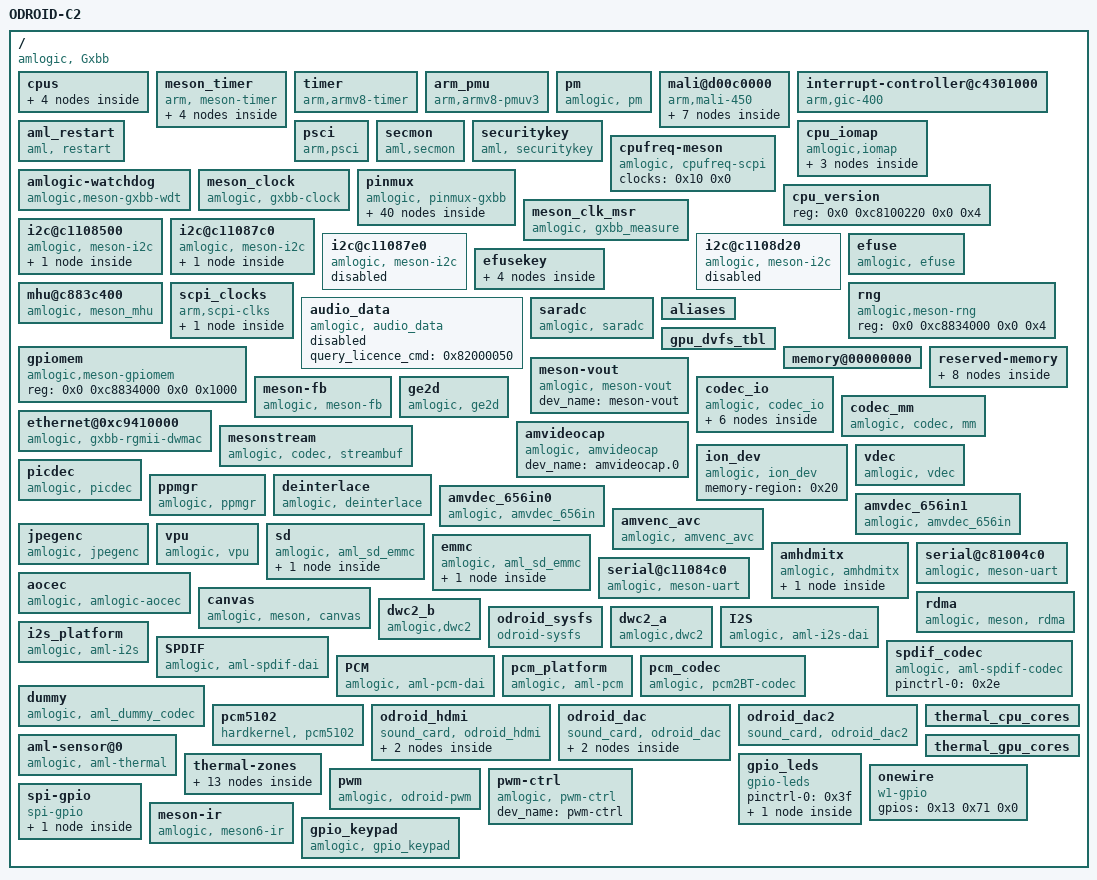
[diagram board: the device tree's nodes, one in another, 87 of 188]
/dts-v1/;

/ {
	compatible = "amlogic, Gxbb";
	model = "ODROID-C2";
	interrupt-parent = <0x1>;
	#address-cells = <0x2>;
	#size-cells = <0x2>;

	cpus {
		#address-cells = <0x2>;
		#size-cells = <0x0>;
		#cooling-cells = <0x2>;
		linux,phandle = <0x3a>;
		phandle = <0x3a>;

		cpu@0 {
			device_type = "cpu";
			compatible = "arm,cortex-a53", "arm,armv8";
			reg = <0x0 0x0>;
			enable-method = "psci";
			timer = <0x2>;
		};

		cpu@1 {
			device_type = "cpu";
			compatible = "arm,cortex-a53", "arm,armv8";
			reg = <0x0 0x1>;
			enable-method = "psci";
			timer = <0x4>;
		};

		cpu@2 {
			device_type = "cpu";
			compatible = "arm,cortex-a53", "arm,armv8";
			reg = <0x0 0x2>;
			enable-method = "psci";
			timer = <0x5>;
		};

		cpu@3 {
			device_type = "cpu";
			compatible = "arm,cortex-a53", "arm,armv8";
			reg = <0x0 0x3>;
			enable-method = "psci";
			timer = <0x6>;
		};
	};

	meson_timer {
		compatible = "arm, meson-timer";
		#address-cells = <0x2>;
		#size-cells = <0x2>;
		ranges;
		reg = <0x0 0xc1109990 0x0 0x4 0x0 0xc1109988 0x0 0x4>;

		timer-f {
			timer_name = "MESON TIMER-F";
			clockevent-rating = <0x12c>;
			clockevent-shift = <0x14>;
			clockevent-features = <0x3>;
			interrupts = <0x0 0x3c 0x1>;
			bit_enable = <0x10>;
			bit_mode = <0xc>;
			bit_resolution = <0x0>;
			reg = <0x0 0xc1109994 0x0 0x4>;
			linux,phandle = <0x2>;
			phandle = <0x2>;
		};

		timer-g {
			timer_name = "MESON TIMER-G";
			clockevent-rating = <0x12c>;
			clockevent-shift = <0x14>;
			clockevent-features = <0x3>;
			interrupts = <0x0 0x3d 0x1>;
			bit_enable = <0x11>;
			bit_mode = <0xd>;
			bit_resolution = <0x2>;
			reg = <0x0 0xc1109998 0x0 0x4>;
			linux,phandle = <0x4>;
			phandle = <0x4>;
		};

		timer-h {
			timer_name = "MESON TIMER-H";
			clockevent-rating = <0x12c>;
			clockevent-shift = <0x14>;
			clockevent-features = <0x3>;
			interrupts = <0x0 0x3e 0x1>;
			bit_enable = <0x12>;
			bit_mode = <0xe>;
			bit_resolution = <0x4>;
			reg = <0x0 0xc110999c 0x0 0x4>;
			linux,phandle = <0x5>;
			phandle = <0x5>;
		};

		timer-i {
			timer_name = "MESON TIMER-I";
			clockevent-rating = <0x12c>;
			clockevent-shift = <0x14>;
			clockevent-features = <0x3>;
			interrupts = <0x0 0x3f 0x1>;
			bit_enable = <0x13>;
			bit_mode = <0xf>;
			bit_resolution = <0x6>;
			reg = <0x0 0xc11099a0 0x0 0x4>;
			linux,phandle = <0x6>;
			phandle = <0x6>;
		};
	};

	timer {
		compatible = "arm,armv8-timer";
		interrupts = <0x1 0xd 0xff01 0x1 0xe 0xff01 0x1 0xb 0xff01 0x1 0xa 0xff01>;
	};

	arm_pmu {
		compatible = "arm,armv8-pmuv3";
		interrupts = <0x0 0x89 0x4 0x0 0x8a 0x4 0x0 0x99 0x4 0x0 0x9a 0x4>;
	};

	pm {
		compatible = "amlogic, pm";
		gxbaby-suspend;
		reg = <0x0 0xc81000a8 0x0 0x4 0x0 0xc810023c 0x0 0x4>;
	};

	mali@d00c0000 {
		#cooling-cells = <0x2>;
		compatible = "arm,mali-450";
		interrupt-parent = <0x1>;
		reg = <0x0 0xd00c0000 0x0 0x40000 0x0 0xc883c000 0x0 0x4 0x0 0xc8100000 0x0 0x4>;
		interrupts = <0x0 0xa0 0x4 0x0 0xa1 0x4 0x0 0xa2 0x4 0x0 0xa3 0x4 0x0 0xa4 0x4 0x0 0xa5 0x4 0x0 0xa6 0x4 0x0 0xa7 0x4 0x0 0xa8 0x4 0x0 0xa9 0x4>;
		interrupt-names = "IRQGP", "IRQGPMMU", "IRQPP", "IRQPMU", "IRQPP0", "IRQPPMMU0", "IRQPP1", "IRQPPMMU1", "IRQPP2", "IRQPPMMU2";
		pmu_domain_config = <0x1 0x2 0x4 0x4 0x0 0x0 0x0 0x0 0x0 0x1 0x2 0x0>;
		pmu_switch_delay = <0xffff>;
		num_of_pp = <0x3>;
		def_clk = <0x4>;
		sc_mpp = <0x3>;
		min_pp = <0x3>;
		min_clk = <0x4>;
		tbl = <0x7 0x8 0x9 0xa 0xb 0xc>;
		clocks = <0xd 0x8 0xd 0x9 0xd 0x11 0xd 0x12 0xd 0x1e 0xd 0x15 0xd 0x13 0xd 0x14>;
		clock-names = "fclk_div3", "fclk_div4", "fclk_div5", "fclk_div7", "gp0_pll", "clk_mali", "clk_mali_0", "clk_mali_1";
		control_interval = <0xc8>;
		dvfs_tbl = <0xe>;
		linux,phandle = <0x3d>;
		phandle = <0x3d>;

		clk125_cfg {
			clk_freq = <0x7735940>;
			clk_parent = "fclk_div4";
			clkp_freq = <0x1dcd6500>;
			voltage = <0x47e>;
			keep_count = <0x5>;
			threshold = <0x1e 0x78>;
			linux,phandle = <0x7>;
			phandle = <0x7>;
		};

		clk250_cfg {
			clk_freq = <0xee6b280>;
			clk_parent = "fclk_div4";
			clkp_freq = <0x1dcd6500>;
			voltage = <0x47e>;
			keep_count = <0x5>;
			threshold = <0x50 0xaa>;
		};

		clk285_cfg {
			clk_freq = <0x10fcc140>;
			clk_parent = "fclk_div7";
			clkp_freq = <0x10fcc140>;
			voltage = <0x47e>;
			keep_count = <0x5>;
			threshold = <0x64 0xbe>;
			linux,phandle = <0x8>;
			phandle = <0x8>;
		};

		clk400_cfg {
			clk_freq = <0x17d78400>;
			clk_parent = "fclk_div5";
			clkp_freq = <0x17d78400>;
			voltage = <0x47e>;
			keep_count = <0x5>;
			threshold = <0x98 0xcf>;
			linux,phandle = <0x9>;
			phandle = <0x9>;
		};

		clk500_cfg {
			clk_freq = <0x1dcd6500>;
			clk_parent = "fclk_div4";
			clkp_freq = <0x1dcd6500>;
			voltage = <0x47e>;
			keep_count = <0x5>;
			threshold = <0xb4 0xdc>;
			linux,phandle = <0xa>;
			phandle = <0xa>;
		};

		clk666_cfg {
			clk_freq = <0x27b25a80>;
			clk_parent = "fclk_div3";
			clkp_freq = <0x27b25a80>;
			voltage = <0x47e>;
			keep_count = <0x5>;
			threshold = <0xd2 0xec>;
			linux,phandle = <0xb>;
			phandle = <0xb>;
		};

		clk800_cfg {
			clk_freq = <0x2f34f600>;
			clk_parent = "gp0_pll";
			clkp_freq = <0x2f34f600>;
			voltage = <0x47e>;
			keep_count = <0x5>;
			threshold = <0xe6 0xff>;
			linux,phandle = <0xc>;
			phandle = <0xc>;
		};
	};

	interrupt-controller@c4301000 {
		compatible = "arm,gic-400", "arm,cortex-a15-gic", "arm,cortex-a9-gic";
		#interrupt-cells = <0x3>;
		#address-cells = <0x0>;
		interrupt-controller;
		reg = <0x0 0xc4301000 0x0 0x1000 0x0 0xc4302000 0x0 0x2000 0x0 0xc4304000 0x0 0x2000 0x0 0xc4306000 0x0 0x2000>;
		interrupts = <0x1 0x9 0xf04>;
		linux,phandle = <0x1>;
		phandle = <0x1>;
	};

	aml_restart {
		compatible = "aml, restart";
		sys_reset = <0x84000009>;
		sys_poweroff = <0x84000008>;
	};

	psci {
		compatible = "arm,psci";
		method = "smc";
		cpu_suspend = <0xc4000001>;
		cpu_off = <0x84000002>;
		cpu_on = <0xc4000003>;
		migrate = <0xc4000005>;
	};

	secmon {
		compatible = "aml,secmon";
		memory-region = <0xf>;
		in_base_func = <0x82000020>;
		out_base_func = <0x82000021>;
	};

	securitykey {
		compatible = "aml, securitykey";
		storage_query = <0x82000060>;
		storage_read = <0x82000061>;
		storage_write = <0x82000062>;
		storage_tell = <0x82000063>;
		storage_verify = <0x82000064>;
		storage_status = <0x82000065>;
		storage_list = <0x82000067>;
		storage_remove = <0x82000068>;
		storage_in_func = <0x82000023>;
		storage_out_func = <0x82000024>;
		storage_block_func = <0x82000025>;
		storage_size_func = <0x82000027>;
	};

	cpu_iomap {
		compatible = "amlogic,iomap";
		#address-cells = <0x2>;
		#size-cells = <0x2>;
		ranges;

		io_cbus_base {
			reg = <0x0 0xc1100000 0x0 0x100000>;
		};

		io_apb_base {
			reg = <0x0 0xd0000000 0x0 0x200000>;
		};

		io_aobus_base {
			reg = <0x0 0xc8100000 0x0 0x100000>;
		};
	};

	cpufreq-meson {
		compatible = "amlogic, cpufreq-scpi";
		status = "okay";
		clocks = <0x10 0x0>;
		clock-names = "cpu_clk";
	};

	amlogic-watchdog {
		compatible = "amlogic,meson-gxbb-wdt";
		status = "okay";
		reg = <0x0 0xc11098d0 0x0 0x10>;
		clocks = <0xd 0x2>;
	};

	meson_clock {
		compatible = "amlogic, gxbb-clock";
		reg = <0x0 0xc883c000 0x0 0x1000 0x0 0xc8100000 0x0 0x1000>;
		#clock-cells = <0x1>;
		#reset-cells = <0x1>;
		sys_max = <0x5b8d8000>;
		linux,phandle = <0xd>;
		phandle = <0xd>;
	};

	pinmux {
		compatible = "amlogic, pinmux-gxbb";
		dev_name = "pinmux";
		#pinmux-cells = <0x2>;
		#address-cells = <0x2>;
		#size-cells = <0x2>;
		reg = <0x0 0xc1109880 0x0 0x10>;
		interrupts = <0x0 0x40 0x1 0x0 0x41 0x1 0x0 0x42 0x1 0x0 0x43 0x1 0x0 0x44 0x1 0x0 0x45 0x1 0x0 0x46 0x1 0x0 0x47 0x1>;
		ranges;

		banks@c11080b0 {
			reg = <0x0 0xc88344b0 0x0 0x28 0x0 0xc88344e8 0x0 0x14 0x0 0xc8834120 0x0 0x14 0x0 0xc8834430 0x0 0x40>;
			reg-names = "mux", "pull", "pull-enable", "gpio";
			gpio-controller;
			#gpio-cells = <0x2>;
			linux,phandle = <0x13>;
			phandle = <0x13>;
		};

		ao-bank@c1108030 {
			reg = <0x0 0xc8100014 0x0 0x8 0x0 0xc810002c 0x0 0x4 0x0 0xc8100024 0x0 0x8>;
			reg-names = "mux", "pull", "gpio";
			gpio-controller;
			#gpio-cells = <0x2>;
			linux,phandle = <0x25>;
			phandle = <0x25>;
		};

		eth_pins {
			amlogic,setmask = <0x6 0x3fff>;
			amlogic,clrmask = <0x6 0xc000 0x5 0x3c0000f0 0x4 0x300>;
			amlogic,pins = "GPIOZ_0", "GPIOZ_1", "GPIOZ_2", "GPIOZ_3", "GPIOZ_4", "GPIOZ_5", "GPIOZ_6", "GPIOZ_7", "GPIOZ_8", "GPIOZ_9", "GPIOZ_10", "GPIOZ_11", "GPIOZ_12", "GPIOZ_13", "GPIOZ_15";
			linux,phandle = <0x1f>;
			phandle = <0x1f>;
		};

		remote_pin {
			amlogic,setmask = <0x10 0x1>;
			amlogic,pins = "GPIOAO_7";
			linux,phandle = <0x42>;
			phandle = <0x42>;
		};

		ao_uart {
			amlogic,setmask = <0x10 0x1800>;
			amlogic,pins = "GPIOAO_0", "GPIOAO_1";
			linux,phandle = <0x2c>;
			phandle = <0x2c>;
		};

		ao_b_uart {
			amlogic,setmask = <0x10 0x1800000>;
			amlogic,pins = "GPIOAO_4", "GPIOAO_5";
		};

		a_uart {
			amlogic,setmask = <0x4 0x3c00>;
			amlogic,pins = "GPIOX_12", "GPIOX_13", "GPIOX_14", "GPIOX_15";
			linux,phandle = <0x2d>;
			phandle = <0x2d>;
		};

		b_uart {
			amlogic,setmask = <0x2 0x30000000>;
			amlogic,pins = "GPIODV_24", "GPIODV_25";
		};

		c_uart {
			amlogic,setmask = <0x1 0xc0000>;
			amlogic,pins = "GPIOY_13", "GPIOY_14";
		};

		wifi_32k_pins {
			amlogic,setmask = <0x2 0x40000000>;
			amlogic,clrmask = <0x2 0x400000 0x3 0x8000>;
			amlogic,pins = "GPIOX_19";
		};

		sd_clk_cmd_pins {
			amlogic,setmask = <0x2 0xc00 0x10 0x1800>;
			amlogic,pins = "CARD_2", "CARD_3";
			amlogic,enable-output = <0x1>;
			amlogic,pullup = <0x1>;
			amlogic,pullupen = <0x1>;
			linux,phandle = <0x23>;
			phandle = <0x23>;
		};

		sd_all_pins {
			amlogic,setmask = <0x2 0xfc00 0x10 0x1800>;
			amlogic,pins = "CARD_0", "CARD_1", "CARD_2", "CARD_3", "CARD_4", "CARD_5";
			amlogic,enable-output = <0x1>;
			amlogic,pullup = <0x1>;
			amlogic,pullupen = <0x1>;
			linux,phandle = <0x24>;
			phandle = <0x24>;
		};

		sd_1bit_pins {
			amlogic,setmask = <0x2 0x8c00 0x10 0x1800>;
			amlogic,pins = "CARD_1", "CARD_2", "CARD_3";
			amlogic,enable-output = <0x1>;
			amlogic,pullup = <0x1>;
			amlogic,pullupen = <0x1>;
		};

		sd_clk_cmd_uart_pins {
			amlogic,setmask = <0x2 0xc00 0x8 0x600>;
			amlogic,pins = "CARD_2", "CARD_3";
			amlogic,enable-output = <0x1>;
			amlogic,pullup = <0x1>;
			amlogic,pullupen = <0x1>;
		};

		sd_1bit_uart_pins {
			amlogic,setmask = <0x2 0x8c00 0x8 0x600>;
			amlogic,pins = "CARD_1", "CARD_2", "CARD_3";
			amlogic,enable-output = <0x1>;
			amlogic,pullup = <0x1>;
			amlogic,pullupen = <0x1>;
		};

		sd_to_ao_uart_pins {
			amlogic,setmask = <0x10 0x1800>;
			amlogic,clrmask = <0x8 0x600>;
			amlogic,pins = "GPIOAO_0", "GPIOAO_1";
			amlogic,enable-output = <0x1>;
			amlogic,pullup = <0x1>;
			amlogic,pullupen = <0x1>;
		};

		ao_to_sd_uart_pins {
			amlogic,setmask = <0x8 0x600>;
			amlogic,clrmask = <0x10 0x1800 0x2 0x3000>;
			amlogic,pins = "CARD_4", "CARD_5";
			amlogic,enable-output = <0x1>;
			amlogic,pullup = <0x1>;
			amlogic,pullupen = <0x1>;
		};

		emmc_clk_cmd_pins {
			amlogic,setmask = <0x4 0xc00c0000>;
			amlogic,pins = "BOOT_8", "BOOT_10";
			amlogic,enable-output = <0x1>;
			amlogic,pullup = <0x1>;
			amlogic,pullupen = <0x1>;
			linux,phandle = <0x26>;
			phandle = <0x26>;
		};

		emmc_all_pins {
			amlogic,setmask = <0x4 0xc00c0000>;
			amlogic,pins = "BOOT_0", "BOOT_1", "BOOT_2", "BOOT_3", "BOOT_4", "BOOT_5", "BOOT_6", "BOOT_7", "BOOT_8", "BOOT_10";
			amlogic,enable-output = <0x1>;
			amlogic,pullup = <0x1>;
			amlogic,pullupen = <0x1>;
			linux,phandle = <0x27>;
			phandle = <0x27>;
		};

		sdio_clk_cmd_pins {
			amlogic,setmask = <0x8 0x3>;
			amlogic,pins = "GPIOX_4", "GPIOX_5";
			amlogic,enable-output = <0x1>;
			amlogic,pullup = <0x1>;
			amlogic,pullupen = <0x1>;
		};

		sdio_all_pins {
			amlogic,setmask = <0x8 0x3f>;
			amlogic,pins = "GPIOX_0", "GPIOX_1", "GPIOX_2", "GPIOX_3", "GPIOX_4", "GPIOX_5";
			amlogic,enable-output = <0x1>;
			amlogic,pullup = <0x1>;
			amlogic,pullupen = <0x1>;
		};

		conf_nand_pulldown {
			amlogic,pins = "BOOT_0", "BOOT_1", "BOOT_2", "BOOT_3", "BOOT_4", "BOOT_5", "BOOT_6", "BOOT_7", "BOOT_15";
			amlogic,pullup = <0x0>;
			amlogic,pullupen = <0x1>;
		};

		conf_nand_pullup {
			amlogic,pins = "BOOT_8", "BOOT_10";
			amlogic,pullup = <0x1>;
			amlogic,pullupen = <0x1>;
		};

		all_nand_pins {
			amlogic,setmask = <0x4 0x7ff00000>;
			amlogic,clrmask = <0x0 0x80000 0x4 0x800c0000 0x5 0xf>;
			amlogic,pins = "BOOT_0", "BOOT_1", "BOOT_2", "BOOT_3", "BOOT_4", "BOOT_5", "BOOT_6", "BOOT_7", "BOOT_8", "BOOT_9", "BOOT_10", "BOOT_11", "BOOT_12", "BOOT_13", "BOOT_14", "BOOT_15", "BOOT_16", "BOOT_17";
			amlogic,enable-output = <0x1>;
		};

		nand_cs {
			amlogic,setmask = <0x4 0xc000000>;
			amlogic,clrmask = <0x4 0x40000>;
			amlogic,pins = "BOOT_8", "BOOT_9";
		};

		hdmitx_hpd {
			amlogic,setmask = <0x1 0x4000000>;
			amlogic,pins = "GPIOH_0";
			linux,phandle = <0x28>;
			phandle = <0x28>;
		};

		hdmitx_ddc {
			amlogic,setmask = <0x1 0x3000000>;
			amlogic,pins = "GPIOH_1", "GPIOH_2";
			linux,phandle = <0x29>;
			phandle = <0x29>;
		};

		hdmitx_aocec {
			amlogic,setmask = <0x10 0x8000>;
			amlogic,clrmask = <0x10 0x24000 0x11 0x1>;
			amlogic,pins = "GPIOAO_12";
			linux,phandle = <0x2b>;
			phandle = <0x2b>;
		};

		hdmitx_eecec {
			amlogic,setmask = <0x10 0x4000>;
			amlogic,clrmask = <0x10 0x28000 0x11 0x1>;
			amlogic,pins = "GPIOAO_12";
		};

		a_i2c {
			amlogic,setmask = <0x7 0xc000000>;
			amlogic,clrmask = <0x0 0x18c0 0x2 0x30000000 0x5 0x1800>;
			amlogic,pins = "GPIODV_24", "GPIODV_25";
			linux,phandle = <0x11>;
			phandle = <0x11>;
		};

		b_i2c {
			amlogic,setmask = <0x7 0x3000000>;
			amlogic,clrmask = <0x0 0x600 0x2 0xc000000 0x5 0x700>;
			amlogic,pins = "GPIODV_26", "GPIODV_27";
			linux,phandle = <0x12>;
			phandle = <0x12>;
		};

		c_i2c {
			amlogic,setmask = <0x7 0xc00000>;
			amlogic,clrmask = <0x3 0x700000>;
			amlogic,pins = "GPIODV_28", "GPIODV_29";
			linux,phandle = <0x14>;
			phandle = <0x14>;
		};

		d_i2c {
			amlogic,setmask = <0x4 0xc>;
			amlogic,clrmask = <0x2 0x3000000 0x3 0x1000>;
			amlogic,pins = "GPIOX_16", "GPIOX_17";
			linux,phandle = <0x15>;
			phandle = <0x15>;
		};

		dvb_p_ts0_pins {
			amlogic,setmask = <0x3 0x37>;
			amlogic,clrmask = <0x2 0xf0000 0x1 0x30ff>;
			amlogic,pins = "GPIOY_0", "GPIOY_1", "GPIOY_2", "GPIOY_3", "GPIOY_4", "GPIOY_5", "GPIOY_6", "GPIOY_7", "GPIOY_8", "GPIOY_9", "GPIOY_10";
		};

		dvb_s_ts0_pins {
			amlogic,setmask = <0x3 0x17>;
			amlogic,clrmask = <0x2 0xf0000 0x1 0x7>;
			amlogic,pins = "GPIOY_0", "GPIOY_1", "GPIOY_2", "GPIOY_3";
		};

		audio_pin {
			amlogic,setmask = <0x10 0x78000000>;
			amlogic,clrmask = <0x10 0x40000>;
			amlogic,pins = "GPIOAO_8", "GPIOAO_9", "GPIOAO_10", "GPIOAO_11";
			linux,phandle = <0x34>;
			phandle = <0x34>;
		};

		audio_pin1 {
			amlogic,setmask = <0x10 0x10000>;
			amlogic,clrmask = <0x10 0x40000>;
			amlogic,pins = "GPIOAO_6";
			linux,phandle = <0x2e>;
			phandle = <0x2e>;
		};

		led_pin {
			amlogic,setmask = <0x10 0x0>;
			amlogic,clrmask = <0x10 0x80000018>;
			amlogic,pins = "GPIOAO_13";
			linux,phandle = <0x3f>;
			phandle = <0x3f>;
		};

		odroid_pwm0 {
			amlogic,setmask = <0x3 0x20000>;
			amlogic,clrmask = <0x3 0x200>;
			amlogic,pins = "GPIOX_6";
			linux,phandle = <0x40>;
			phandle = <0x40>;
		};

		odroid_pwm1 {
			amlogic,setmask = <0x3 0x20000 0x3 0x60000>;
			amlogic,clrmask = <0x3 0x300 0x8 0x800>;
			amlogic,pins = "GPIOX_6", "GPIOX_7";
			linux,phandle = <0x41>;
			phandle = <0x41>;
		};
	};

	cpu_version {
		reg = <0x0 0xc8100220 0x0 0x4>;
	};

	meson_clk_msr {
		compatible = "amlogic, gxbb_measure";
		reg = <0x0 0xc110875c 0x0 0x4 0x0 0xc1108764 0x0 0x4>;
	};

	i2c@c1108500 {
		compatible = "amlogic, meson-i2c";
		dev_name = "i2c-A";
		status = "okay";
		reg = <0x0 0xc1108500 0x0 0x20>;
		device_id = <0x1>;
		pinctrl-names = "default";
		pinctrl-0 = <0x11>;
		#address-cells = <0x1>;
		#size-cells = <0x0>;
		use_pio = <0x0>;
		master_i2c_speed = <0x493e0>;
		clocks = <0xd 0xa>;
		clock-names = "clk_i2c";
		resets = <0xd 0x9>;

		pcf8563@51 {
			status = "disabled";
			compatible = "nxp,pcf8563";
			reg = <0x51>;
			#clock-cells = <0x0>;
		};
	};

	i2c@c11087c0 {
		compatible = "amlogic, meson-i2c";
		dev_name = "i2c-B";
		status = "okay";
		reg = <0x0 0xc11087c0 0x0 0x20>;
		device_id = <0x2>;
		pinctrl-names = "default";
		pinctrl-0 = <0x12>;
		#address-cells = <0x1>;
		#size-cells = <0x0>;
		use_pio = <0x0>;
		master_i2c_speed = <0x493e0>;
		clocks = <0xd 0xa>;
		clock-names = "clk_i2c";
		resets = <0xd 0x9>;

		sx865x@49 {
			status = "okay";
			compatible = "semtech,sx8650";
			reg = <0x49>;
			#clock-cells = <0x0>;
			gpio-pendown = <0x13 0x52 0x0>;
			gpio-reset = <0x13 0x58 0x0>;
			invert-x = <0x0>;
			invert-y = <0x1>;
			swap-xy = <0x1>;
		};
	};

	i2c@c11087e0 {
		compatible = "amlogic, meson-i2c";
		dev_name = "i2c-C";
		status = "disabled";
		reg = <0x0 0xc11087e0 0x0 0x20>;
		device_id = <0x3>;
		pinctrl-names = "default";
		pinctrl-0 = <0x14>;
		#address-cells = <0x1>;
		#size-cells = <0x0>;
		use_pio = <0x0>;
		master_i2c_speed = <0x493e0>;
		clocks = <0xd 0xa>;
		clock-names = "clk_i2c";
		resets = <0xd 0x9>;
	};

	i2c@c1108d20 {
		compatible = "amlogic, meson-i2c";
		dev_name = "i2c-D";
		status = "disabled";
		reg = <0x0 0xc1108d20 0x0 0x20>;
		device_id = <0x4>;
		pinctrl-names = "default";
		pinctrl-0 = <0x15>;
		#address-cells = <0x1>;
		#size-cells = <0x0>;
		use_pio = <0x0>;
		master_i2c_speed = <0x493e0>;
		clocks = <0xd 0xa>;
		clock-names = "clk_i2c";
		resets = <0xd 0x9>;
	};

	efuse {
		compatible = "amlogic, efuse";
		read_cmd = <0x82000030>;
		write_cmd = <0x82000031>;
		get_max_cmd = <0x82000033>;
		key = <0x16>;
		resets = <0xd 0x3e>;
		reset-names = "efuse_clk";
		status = "okay";
	};

	efusekey {
		keynum = <0x4>;
		key0 = <0x17>;
		key1 = <0x18>;
		key2 = <0x19>;
		key3 = <0x1a>;
		linux,phandle = <0x16>;
		phandle = <0x16>;

		key0 {
			keyname = "mac";
			offset = <0x0>;
			size = <0x6>;
			linux,phandle = <0x17>;
			phandle = <0x17>;
		};

		key1 {
			keyname = "mac_bt";
			offset = <0x6>;
			size = <0x6>;
			linux,phandle = <0x18>;
			phandle = <0x18>;
		};

		key2 {
			keyname = "mac_wifi";
			offset = <0xc>;
			size = <0x6>;
			linux,phandle = <0x19>;
			phandle = <0x19>;
		};

		key3 {
			keyname = "usid";
			offset = <0x12>;
			size = <0x10>;
			linux,phandle = <0x1a>;
			phandle = <0x1a>;
		};
	};

	mhu@c883c400 {
		compatible = "amlogic, meson_mhu";
		reg = <0x0 0xc883c400 0x0 0x4c 0x0 0xc8013000 0x0 0x800>;
		interrupts = <0x0 0xd1 0x8 0x0 0xd2 0x8>;
		#mbox-cells = <0x1>;
		mbox-names = "cpu_to_scp_low", "cpu_to_scp_high";
		mboxes = <0x1b 0x0 0x1b 0x1>;
		linux,phandle = <0x1b>;
		phandle = <0x1b>;
	};

	scpi_clocks {
		compatible = "arm,scpi-clks";

		scpi_clocks@0 {
			compatible = "arm,scpi-clk-indexed";
			#clock-cells = <0x1>;
			clock-indices = <0x0>;
			clock-output-names = "vcpu";
			linux,phandle = <0x10>;
			phandle = <0x10>;
		};
	};

	rng {
		compatible = "amlogic,meson-rng";
		reg = <0x0 0xc8834000 0x0 0x4>;
	};

	audio_data {
		compatible = "amlogic, audio_data";
		query_licence_cmd = <0x82000050>;
		status = "disabled";
	};

	saradc {
		compatible = "amlogic, saradc";
		status = "okay";
		interrupts = <0x0 0x9 0x1>;
		interrupt-names = "saradc_int";
		clocks = <0xd 0x2>;
		clock-names = "saradc_clk";
		resets = <0xd 0x56>;
		reg = <0x0 0xc1108680 0x0 0x30 0x0 0xc883c3d8 0x0 0x8>;
	};

	aliases {
		serial0 = "/serial@c81004c0";
		serial1 = "/serial@c11084c0";
	};

	gpu_dvfs_tbl {
		sc_mpp = <0x3>;
		tbl = <0x8 0x9 0xa 0xb 0xc>;
		linux,phandle = <0xe>;
		phandle = <0xe>;
	};

	gpiomem {
		compatible = "amlogic,meson-gpiomem";
		reg = <0x0 0xc8834000 0x0 0x1000>;
		status = "okay";
	};

	memory@00000000 {
		device_type = "memory";
		linux,usable-memory = <0x0 0x1000000 0x0 0x7f000000>;
	};

	reserved-memory {
		#address-cells = <0x2>;
		#size-cells = <0x2>;
		ranges;

		linux,secmon {
			compatible = "aml_secmon_memory";
			reg = <0x0 0x10000000 0x0 0x200000>;
			no-map;
			linux,phandle = <0xf>;
			phandle = <0xf>;
		};

		linux,meson-fb {
			compatible = "amlogic, fb-memory";
			size = <0x0 0x8000000>;
			no-map;
			linux,phandle = <0x1c>;
			phandle = <0x1c>;
		};

		linux,di {
			compatible = "amlogic, di-mem";
			size = <0x0 0x1e00000>;
			multi-use;
			linux,phandle = <0x22>;
			phandle = <0x22>;
		};

		linux,ion-dev {
			compatible = "amlogic, idev-mem";
			size = <0x0 0x2000000>;
			multi-use;
			linux,phandle = <0x20>;
			phandle = <0x20>;
		};

		linux,codec_mm_cma {
			compatible = "shared-dma-pool";
			reusable;
			size = <0x0 0xbc00000>;
			alignment = <0x0 0x400000>;
			linux,contiguous-region;
			linux,phandle = <0x1d>;
			phandle = <0x1d>;
		};

		linux,picdec {
			compatible = "shared-dma-pool";
			reusable;
			size = <0x0 0x3000000>;
			alignment = <0x0 0x400000>;
			linux,contiguous-region;
			linux,phandle = <0x21>;
			phandle = <0x21>;
		};

		linux,codec_mm_reserved {
			compatible = "amlogic, codec-mm-reserved";
			size = <0x0 0x4100000>;
			alignment = <0x0 0x100000>;
			linux,phandle = <0x1e>;
			phandle = <0x1e>;
		};

		linux,jpegenc_cma {
			compatible = "shared-dma-pool";
			linux,phandle = <0x3>;
			reusable;
			size = <0x0 0x2400000>;
			alignment = <0x0 0x400000>;
		};
	};

	meson-vout {
		compatible = "amlogic, meson-vout";
		dev_name = "meson-vout";
		status = "okay";
	};

	meson-fb {
		compatible = "amlogic, meson-fb";
		memory-region = <0x1c>;
		dev_name = "meson-fb";
		status = "okay";
		interrupts = <0x0 0x3 0x1 0x0 0x59 0x1>;
		interrupt-names = "viu-vsync", "rdma";
		mem_size = <0x6000000 0x100000>;
		vmode = <0x3>;
		scale_mode = <0x1>;
		4k2k_fb = <0x1>;
		display_size_default = <0x780 0x438 0x780 0x870 0x20>;
	};

	ge2d {
		compatible = "amlogic, ge2d";
		dev_name = "ge2d";
		status = "okay";
		interrupts = <0x0 0x96 0x1>;
		interrupt-names = "ge2d";
		clocks = <0xd 0x17 0xd 0x19>;
		clock-names = "clk_vapb_0", "clk_ge2d";
		resets = <0xd 0x34>;
		reset-names = "ge2d";
	};

	codec_io {
		compatible = "amlogic, codec_io";
		#address-cells = <0x2>;
		#size-cells = <0x2>;
		ranges;

		io_cbus_base {
			reg = <0x0 0xc1100000 0x0 0x100000>;
		};

		io_dos_base {
			reg = <0x0 0xc8820000 0x0 0x10000>;
		};

		io_hiubus_base {
			reg = <0x0 0xc883c000 0x0 0x2000>;
		};

		io_aobus_base {
			reg = <0x0 0xc8100000 0x0 0x100000>;
		};

		io_vcbus_base {
			reg = <0x0 0xd0100000 0x0 0x40000>;
		};

		io_dmc_base {
			reg = <0x0 0xc8838000 0x0 0x400>;
		};
	};

	codec_mm {
		compatible = "amlogic, codec, mm";
		memory-region = <0x1d 0x1e>;
		dev_name = "codec_mm";
		status = "okay";
	};

	ethernet@0xc9410000 {
		compatible = "amlogic, gxbb-rgmii-dwmac";
		reg = <0x0 0xc9410000 0x0 0x10000 0x0 0xc8834540 0x0 0x8>;
		interrupts = <0x0 0x8 0x1>;
		phy-mode = "rgmii";
		pinctrl-names = "eth_pins";
		pinctrl-0 = <0x1f>;
		rst_pin-gpios = <0x13 0xe 0x0>;
		mc_val = <0x1621>;
		resets = <0xd 0x23>;
		reset-names = "ethpower";
		interrupt-names = "macirq";
		clocks = <0xd 0xa>;
		clock-names = "ethclk81";
		max-frame-size = <0xdfe>;
	};

	mesonstream {
		compatible = "amlogic, codec, streambuf";
		dev_name = "mesonstream";
		status = "okay";
		resets = <0xd 0x39 0xd 0x59 0xd 0x24 0xd 0x1>;
		reset-names = "parser_top", "vpu_intr", "demux", "vdec";
	};

	amvideocap {
		compatible = "amlogic, amvideocap";
		dev_name = "amvideocap.0";
		status = "okay";
	};

	ion_dev {
		compatible = "amlogic, ion_dev";
		memory-region = <0x20>;
	};

	vdec {
		compatible = "amlogic, vdec";
		dev_name = "vdec.0";
		status = "okay";
		interrupts = <0x0 0x3 0x1 0x0 0x17 0x1 0x0 0x20 0x1 0x0 0x2b 0x1 0x0 0x2c 0x1 0x0 0x2d 0x1>;
		interrupt-names = "vsync", "demux", "parser", "mailbox_0", "mailbox_1", "mailbox_2";
	};

	picdec {
		compatible = "amlogic, picdec";
		memory-region = <0x21>;
		dev_name = "picdec";
		status = "okay";
	};

	ppmgr {
		compatible = "amlogic, ppmgr";
		memory-region = <0x20>;
		dev_name = "ppmgr";
		status = "okay";
	};

	deinterlace {
		compatible = "amlogic, deinterlace";
		status = "okay";
		memory-region = <0x22>;
		interrupts = <0x0 0x2e 0x1 0x0 0x6 0x1>;
		interrupt-names = "de_irq", "timerc";
		buffer-size = <0x2fd000>;
		hw-version = <0x2>;
	};

	amvdec_656in0 {
		compatible = "amlogic, amvdec_656in";
		dev_name = "amvdec_656in0";
		status = "ok";
		reg = <0x0 0xd0048000 0x0 0x7c>;
		clocks = <0xd 0x7 0xd 0x26>;
		clock-names = "fclk_div2", "cts_bt656_clk0";
		bt656_id = <0x0>;
	};

	amvdec_656in1 {
		compatible = "amlogic, amvdec_656in";
		dev_name = "amvdec_656in1";
		status = "ok";
		reg = <0x0 0xd0050000 0x0 0x7c>;
		clocks = <0xd 0x7 0xd 0x27>;
		clock-names = "fclk_div2", "cts_bt656_clk1";
		bt656_id = <0x1>;
	};

	amvenc_avc {
		compatible = "amlogic, amvenc_avc";
		dev_name = "amvenc_avc";
		status = "okay";
		interrupts = <0x0 0x2d 0x1>;
		interrupt-names = "mailbox_2";
	};

	jpegenc {
		compatible = "amlogic, jpegenc";
		memory-region = <0x3>;
		dev_name = "jpegenc";
		status = "okay";
		interrupts = <0x0 0x2d 0x1>;
		interrupt-names = "mailbox_2";
	};

	vpu {
		compatible = "amlogic, vpu";
		dev_name = "vpu";
		status = "ok";
		clk_level = <0x7>;
	};

	sd {
		compatible = "amlogic, aml_sd_emmc";
		dev_name = "aml_newsd.0";
		status = "okay";
		reg = <0x0 0xd0072000 0x0 0x2000>;
		interrupts = <0x0 0xd9 0x1 0x0 0x43 0x1 0x0 0x45 0x1>;
		pinctrl-names = "sd_clk_cmd_pins", "sd_all_pins";
		pinctrl-0 = <0x23>;
		pinctrl-1 = <0x24>;

		sd {
			status = "okay";
			pinname = "sd";
			ocr_avail = <0x200080>;
			caps = "MMC_CAP_4_BIT_DATA", "MMC_CAP_MMC_HIGHSPEED", "MMC_CAP_SD_HIGHSPEED", "MMC_CAP_UHS_SDR50", "MMC_CAP_UHS_SDR104";
			f_min = <0x61a80>;
			f_max = <0x510ff40>;
			max_req_size = <0x20000>;
			gpio_dat3 = <0x13 0x2a 0x0>;
			jtag_pin = <0x13 0x26 0x0>;
			gpio_cd = <0x13 0x2c 0x0>;
			gpio_volsw = <0x25 0x3 0x1>;
			gpio_power = <0x13 0x57 0x0>;
			power_level = <0x1>;
			irq_in = <0x3>;
			irq_out = <0x5>;
			card_type = <0x5>;
		};
	};

	emmc {
		compatible = "amlogic, aml_sd_emmc";
		dev_name = "aml_newsd.0";
		status = "okay";
		reg = <0x0 0xd0074000 0x0 0x2000>;
		interrupts = <0x0 0xda 0x1>;
		pinctrl-names = "emmc_clk_cmd_pins", "emmc_all_pins";
		pinctrl-0 = <0x26>;
		pinctrl-1 = <0x27>;

		emmc {
			status = "okay";
			pinname = "emmc";
			ocr_avail = <0x200080>;
			caps = "MMC_CAP_8_BIT_DATA", "MMC_CAP_MMC_HIGHSPEED", "MMC_CAP_SD_HIGHSPEED", "MMC_CAP_NONREMOVABLE", "MMC_CAP_1_8V_DDR", "MMC_CAP_HW_RESET", "MMC_CAP_ERASE";
			caps2 = "MMC_CAP2_HS200_1_8V_SDR", "MMC_CAP2_HS400_1_8V", "MMC_CAP2_BROKEN_VOLTAGE", "MMC_CAP2_BOOTPART_NOACC";
			f_min = <0x61a80>;
			f_max = <0x5f5e100>;
			max_req_size = <0x20000>;
			gpio_dat3 = <0x13 0x17 0x0>;
			hw_reset = <0x13 0x1d 0x0>;
			card_type = <0x1>;
		};
	};

	amhdmitx {
		compatible = "amlogic, amhdmitx";
		dev_name = "amhdmitx";
		status = "okay";
		pinctrl-names = "hdmitx_hpd", "hdmitx_ddc";
		pinctrl-0 = <0x28>;
		pinctrl-1 = <0x29>;
		vend-data = <0x2a>;
		interrupts = <0x0 0x39 0x1>;
		interrupt-names = "hdmitx_hpd";
		clocks = <0xd 0xb 0xd 0xc 0xd 0xd 0xd 0xe 0xd 0xf 0xd 0x16>;
		clock-names = "hdmitx_clk_sys", "hdmitx_clk_encp", "hdmitx_clk_enci", "hdmitx_clk_pixel", "hdmitx_clk_phy", "hdmitx_clk_vid";

		vend_data {
			compatible = "amlogic, amlogic-cec";
			status = "okay";
			vendor_name = "Hardkernel";
			vendor_id = <0x0>;
			product_desc = "ODROID-C2";
			cec_osd_string = "ODROID-C2";
			interrupts = <0x0 0xc7 0x1>;
			interrupt-names = "hdmitx_cec";
			pinctrl-names = "hdmitx_aocec";
			pinctrl-0 = <0x2b>;
			linux,phandle = <0x2a>;
			phandle = <0x2a>;
		};
	};

	aocec {
		compatible = "amlogic, amlogic-aocec";
		device_name = "aocec";
		status = "okay";
		vendor_name = "Hardkernel";
		vendor_id = <0x0>;
		product_desc = "ODROID-C2";
		cec_osd_string = "ODROID-C2";
		port_num = <0x3>;
		arc_port_mask = <0x0>;
		interrupts = <0x0 0xc7 0x1>;
		interrupt-names = "hdmi_aocec";
		pinctrl-names = "hdmitx_aocec";
		pinctrl-0 = <0x2b>;
		reg = <0x0 0xc810023c 0x0 0x4 0x0 0xc8100000 0x0 0x200 0x0 0xda83e000 0x0 0x10>;
	};

	serial@c81004c0 {
		compatible = "amlogic, meson-uart";
		reg = <0x0 0xc81004c0 0x0 0x14>;
		interrupts = <0x0 0xc1 0x1>;
		status = "okay";
		clocks = <0xd 0x2>;
		clock-names = "clk_uart";
		fifosize = <0x40>;
		pinctrl-names = "default";
		pinctrl-0 = <0x2c>;
	};

	serial@c11084c0 {
		compatible = "amlogic, meson-uart";
		reg = <0x0 0xc11084c0 0x0 0x14>;
		interrupts = <0x0 0x1a 0x1>;
		status = "okay";
		clocks = <0xd 0x2>;
		clock-names = "clk_uart";
		fifosize = <0x80>;
		pinctrl-names = "default";
		pinctrl-0 = <0x2d>;
	};

	canvas {
		compatible = "amlogic, meson, canvas";
		dev_name = "amlogic-canvas";
		status = "ok";
		reg = <0x0 0xc8838000 0x0 0x400>;
	};

	rdma {
		compatible = "amlogic, meson, rdma";
		dev_name = "amlogic-rdma";
		status = "ok";
		interrupts = <0x0 0x59 0x1>;
		interrupt-names = "rdma";
	};

	dwc2_b {
		compatible = "amlogic,dwc2";
		reg = <0x0 0xc9100000 0x0 0x40000>;
		interrupts = <0x0 0x1f 0x4>;
		status = "okay";
		pl-periph-id = <0x1>;
		clock-src = "usb1";
		port-id = <0x1>;
		port-type = <0x1>;
		port-speed = <0x0>;
		port-config = <0x0>;
		port-dma = <0x0>;
		port-id-mode = <0x1>;
		gpio-hub-rst = "GPIOAO_4";
		gpios = <0x25 0x4 0x0>;
		phy-reg = <0xc0000020>;
		phy-reg-size = <0x20>;
		usb-fifo = <0x400>;
		host-only-core = <0x1>;
		pmu-apply-power = <0x1>;
		cpu-type = "gxbaby";
		resets = <0xd 0x3a 0xd 0x48 0xd 0x36>;
		reset-names = "usb_general", "usb1", "usb1_to_ddr";
	};

	odroid_sysfs {
		compatible = "odroid-sysfs";
	};

	dwc2_a {
		compatible = "amlogic,dwc2";
		reg = <0x0 0xc9000000 0x0 0x40000>;
		interrupts = <0x0 0x1e 0x4>;
		status = "okay";
		pl-periph-id = <0x0>;
		clock-src = "usb0";
		port-id = <0x0>;
		port-type = <0x0>;
		port-speed = <0x0>;
		port-config = <0x0>;
		port-dma = <0x0>;
		port-id-mode = <0x0>;
		gpio-vbus-power = "GPIOAO_5";
		gpios = <0x25 0x5 0x0>;
		gpio-work-mask = <0x1>;
		phy-reg = <0xc0000000>;
		phy-reg-size = <0x20>;
		usb-fifo = <0x400>;
		cpu-type = "gxbaby";
		resets = <0xd 0x3a 0xd 0x49 0xd 0x35>;
		reset-names = "usb_general", "usb0", "usb0_to_ddr";
	};

	I2S {
		compatible = "amlogic, aml-i2s-dai";
		#sound-dai-cells = <0x0>;
		resets = <0xd 0x26 0xd 0x12 0xd 0x28 0xd 0x29 0xd 0x2a 0xd 0x2b 0xd 0x2c 0xd 0x2d 0xd 0x2f 0xd 0x8e 0xd 0x22>;
		reset-names = "top_glue", "aud_buf", "i2s_out", "amclk_measure", "aififo2", "aud_mixer", "mixer_reg", "adc", "top_level", "aoclk", "aud_in";
		clocks = <0xd 0x1f 0xd 0x22>;
		clock-names = "mpll0", "mclk";
		linux,phandle = <0x32>;
		phandle = <0x32>;
	};

	i2s_platform {
		compatible = "amlogic, aml-i2s";
		linux,phandle = <0x31>;
		phandle = <0x31>;
	};

	SPDIF {
		compatible = "amlogic, aml-spdif-dai";
		#sound-dai-cells = <0x0>;
		resets = <0xd 0x27 0xd 0x90>;
		reset-names = "iec958", "iec958_amclk";
		clocks = <0xd 0x20 0xd 0x24 0xd 0x22 0xd 0x25>;
		clock-names = "mpll1", "i958", "mclk", "spdif";
	};

	spdif_codec {
		#sound-dai-cells = <0x0>;
		compatible = "amlogic, aml-spdif-codec";
		pinctrl-names = "aml_audio_spdif";
		pinctrl-0 = <0x2e>;
		linux,phandle = <0x33>;
		phandle = <0x33>;
	};

	PCM {
		#sound-dai-cells = <0x0>;
		compatible = "amlogic, aml-pcm-dai";
	};

	pcm_platform {
		compatible = "amlogic, aml-pcm";
	};

	pcm_codec {
		#sound-dai-cells = <0x0>;
		compatible = "amlogic, pcm2BT-codec";
	};

	dummy {
		#sound-dai-cells = <0x0>;
		compatible = "amlogic, aml_dummy_codec";
		status = "okay";
	};

	pcm5102 {
		#sound-dai-cells = <0x0>;
		compatible = "hardkernel, pcm5102";
		status = "okay";
		linux,phandle = <0x37>;
		phandle = <0x37>;
	};

	odroid_hdmi {
		compatible = "sound_card, odroid_hdmi";
		status = "okay";
		aml-sound-card,format = "i2s";
		aml_sound_card,name = "ODROID-HDMI";
		cpu_list = <0x2f>;
		codec_list = <0x30>;
		plat_list = <0x31>;

		i2sdai0 {
			sound-dai = <0x32>;
			linux,phandle = <0x2f>;
			phandle = <0x2f>;
		};

		dit0 {
			sound-dai = <0x33>;
			linux,phandle = <0x30>;
			phandle = <0x30>;
		};
	};

	odroid_dac {
		compatible = "sound_card, odroid_dac";
		status = "okay";
		aml-sound-card,format = "i2s";
		aml_sound_card,name = "ODROID-DAC";
		pinctrl-names = "aml_snd_i2s";
		pinctrl-0 = <0x34>;
		cpu_list = <0x35>;
		codec_list = <0x36>;
		plat_list = <0x31>;

		cpudai0 {
			sound-dai = <0x32>;
			linux,phandle = <0x35>;
			phandle = <0x35>;
		};

		codec0 {
			sound-dai = <0x37>;
			linux,phandle = <0x36>;
			phandle = <0x36>;
		};
	};

	odroid_dac2 {
		compatible = "sound_card, odroid_dac2";
		aml,sound_card = "ODROID-DAC2";
		pinctrl-names = "odroid_i2s";
		pinctrl-0 = <0x34>;
		status = "okay";
	};

	aml-sensor@0 {
		compatible = "amlogic, aml-thermal";
		#thermal-sensor-cells = <0x1>;
		cpu_dyn_coeff = <0x8c>;
		min_state = <0x7a120 0x190 0x1 0x2>;
		gpu_dyn_coeff = <0x1b5>;
		linux,phandle = <0x38>;
		phandle = <0x38>;
	};

	thermal_cpu_cores {
		#cooling-cells = <0x2>;
		linux,phandle = <0x3c>;
		phandle = <0x3c>;
	};

	thermal_gpu_cores {
		#cooling-cells = <0x2>;
		linux,phandle = <0x3e>;
		phandle = <0x3e>;
	};

	thermal-zones {

		soc_thermal {
			polling-delay = <0x3e8>;
			polling-delay-passive = <0x64>;
			sustainable-power = <0xe10>;
			thermal-sensors = <0x38 0x3>;

			trips {

				trip-point@0 {
					temperature = <0x14c08>;
					hysteresis = <0x3e8>;
					type = "passive";
				};

				trip-point@1 {
					temperature = <0x15f90>;
					hysteresis = <0x3e8>;
					type = "passive";
					linux,phandle = <0x39>;
					phandle = <0x39>;
				};

				trip-point@2 {
					temperature = <0x186a0>;
					hysteresis = <0x3e8>;
					type = "passive";
					linux,phandle = <0x3b>;
					phandle = <0x3b>;
				};

				trip-point@3 {
					temperature = <0x19a28>;
					hysteresis = <0x3e8>;
					type = "critical";
				};
			};

			cooling-maps {

				cpufreq_cooling_map0 {
					trip = <0x39>;
					cooling-device = <0x3a 0x0 0x2>;
					contribution = <0x64>;
				};

				cpufreq_cooling_map1 {
					trip = <0x3b>;
					cooling-device = <0x3a 0x3 0x4>;
					contribution = <0x64>;
				};

				cpucore_cooling_map {
					trip = <0x39>;
					cooling-device = <0x3c 0x0 0x2>;
					contribution = <0x400>;
				};

				gpufreq_cooling_map0 {
					trip = <0x39>;
					cooling-device = <0x3d 0x0 0x2>;
					contribution = <0x64>;
				};

				gpufreq_cooling_map1 {
					trip = <0x3b>;
					cooling-device = <0x3d 0x3 0x4>;
					contribution = <0x64>;
				};

				gpucore_cooling_map {
					trip = <0x39>;
					cooling-device = <0x3e 0x0 0x2>;
					contribution = <0x400>;
				};
			};
		};
	};

	gpio_leds {
		compatible = "gpio-leds";
		pinctrl-names = "led_pins";
		pinctrl-0 = <0x3f>;

		heartbeat {
			label = "blue:heartbeat";
			gpios = <0x25 0xd 0x1>;
			linux,default-trigger = "heartbeat";
		};
	};

	onewire {
		compatible = "w1-gpio";
		gpios = <0x13 0x71 0x0>;
	};

	pwm {
		compatible = "amlogic, odroid-pwm";
		dev_name = "meson_pwm";
		status = "ok";
		pinctrl-names = "odroid_pwm0", "odroid_pwm1";
		pinctrl-0 = <0x40>;
		pinctrl-1 = <0x41>;
	};

	pwm-ctrl {
		compatible = "amlogic, pwm-ctrl";
		dev_name = "pwm-ctrl";
		status = "ok";
	};

	spi-gpio {
		compatible = "spi-gpio";
		#address-cells = <0x1>;
		#size-cells = <0x0>;
		status = "ok";
		id = <0x0>;
		gpio-sck = <0x13 0x5e 0x0>;
		gpio-miso = <0x13 0x60 0x0>;
		gpio-mosi = <0x13 0x63 0x0>;
		cs-gpios = <0x13 0x5d 0x0 0x13 0x59 0x0>;
		num-chipselects = <0x2>;

		spi-gpio@0 {
			compatible = "spidev";
			reg = <0x0>;
			spi-max-frequency = <0x7a120>;
		};
	};

	meson-ir {
		compatible = "amlogic, meson6-ir";
		reg = <0x0 0xc8100580 0x0 0x20>;
		interrupts = <0x0 0xc4 0x1>;
		pinctrl-names = "default";
		pinctrl-0 = <0x42>;
		pulse-inverted;
		status = "ok";
	};

	gpio_keypad {
		compatible = "amlogic, gpio_keypad";
		status = "okay";
		scan_period = <0x14>;
		key_num = <0x1>;
		key_name = "power";
		key_code = <0x74>;
		irq_keyup = <0x6>;
		irq_keydown = <0x7>;
		reg = <0x0 0xc8100000 0x0 0x200>;
	};
};
